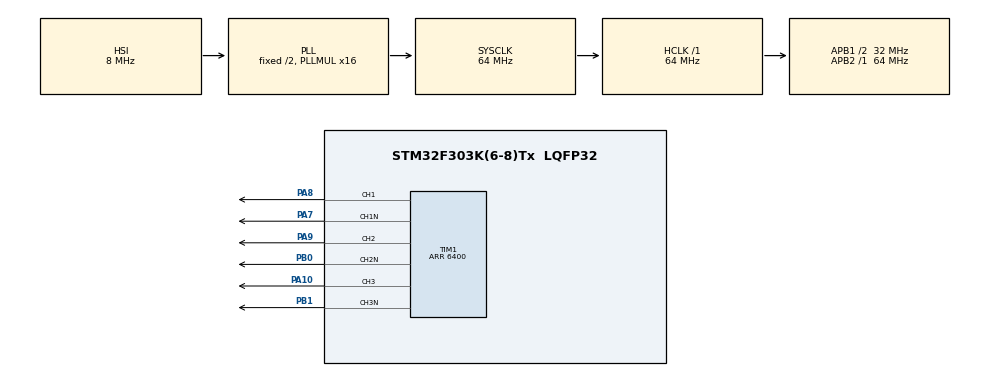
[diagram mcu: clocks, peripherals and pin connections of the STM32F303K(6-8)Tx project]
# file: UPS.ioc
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Mcu.Family=STM32F3
Mcu.Name=STM32F303K(6-8)Tx
Mcu.Package=LQFP32
NVIC.PriorityGroup=NVIC_PRIORITYGROUP_4
NVIC.TIM6_DAC1_IRQn=true\:0\:0\:false\:false\:true\:true
PA10.GPIO_ModeDefaultPP=GPIO_MODE_AF_OD
PA10.GPIO_PuPd=GPIO_PULLUP
PA10.GPIO_Speed=GPIO_SPEED_FREQ_HIGH
PA10.Signal=S_TIM1_CH3
PA7.GPIO_ModeDefaultPP=GPIO_MODE_AF_OD
PA7.GPIO_PuPd=GPIO_PULLUP
PA7.GPIO_Speed=GPIO_SPEED_FREQ_HIGH
PA7.Mode=PWM Generation1 CH1 CH1N
PA7.Signal=TIM1_CH1N
PA8.GPIO_ModeDefaultPP=GPIO_MODE_AF_OD
PA8.GPIO_PuPd=GPIO_PULLUP
PA8.GPIO_Speed=GPIO_SPEED_FREQ_HIGH
PA8.Signal=S_TIM1_CH1
PA9.GPIO_ModeDefaultPP=GPIO_MODE_AF_OD
PA9.GPIO_PuPd=GPIO_PULLUP
PA9.GPIO_Speed=GPIO_SPEED_FREQ_HIGH
PA9.Signal=S_TIM1_CH2
PB0.GPIO_ModeDefaultPP=GPIO_MODE_AF_OD
PB0.GPIO_PuPd=GPIO_PULLUP
PB0.GPIO_Speed=GPIO_SPEED_FREQ_HIGH
PB0.Mode=PWM Generation2 CH2 CH2N
PB0.Signal=TIM1_CH2N
PB1.GPIO_ModeDefaultPP=GPIO_MODE_AF_OD
PB1.GPIO_PuPd=GPIO_PULLUP
PB1.GPIO_Speed=GPIO_SPEED_FREQ_HIGH
PB1.Mode=PWM Generation3 CH3 CH3N
PB1.Signal=TIM1_CH3N
ProjectManager.HeapSize=0x200
ProjectManager.StackSize=0x400
ProjectManager.TargetToolchain=MDK-ARM V5
RCC.AHBFreq_Value=64000000
RCC.APB1CLKDivider=RCC_HCLK_DIV2
RCC.APB1Freq_Value=32000000
RCC.APB1TimFreq_Value=64000000
RCC.APB2Freq_Value=64000000
RCC.APB2TimFreq_Value=64000000
RCC.CortexFreq_Value=64000000
RCC.HCLKFreq_Value=64000000
RCC.HSE_VALUE=8000000
RCC.HSI_VALUE=8000000
RCC.PLLMUL=RCC_PLL_MUL16
RCC.SYSCLKFreq_VALUE=64000000
RCC.SYSCLKSourceVirtual=RCC_SYSCLKSOURCE_PLLCLK
SH.S_TIM1_CH1.0=TIM1_CH1,PWM Generation1 CH1 CH1N
SH.S_TIM1_CH2.0=TIM1_CH2,PWM Generation2 CH2 CH2N
SH.S_TIM1_CH3.0=TIM1_CH3,PWM Generation3 CH3 CH3N
TIM1.Channel-PWM\ Generation1\ CH1\ CH1N=TIM_CHANNEL_1
TIM1.Channel-PWM\ Generation2\ CH2\ CH2N=TIM_CHANNEL_2
TIM1.Channel-PWM\ Generation3\ CH3\ CH3N=TIM_CHANNEL_3
TIM1.DeadTime=50
TIM1.Period=6400
TIM6.Period=6400
VP_TIM1_VS_ClockSourceINT.Mode=Internal
VP_TIM6_VS_ClockSourceINT.Mode=Enable_Timer
board=UPS

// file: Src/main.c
/**
  ******************************************************************************
  * File Name          : main.c
  * Description        : Main program body
  ******************************************************************************
  ** This notice applies to any and all portions of this file
  * that are not between comment pairs USER CODE BEGIN and
  * USER CODE END. Other portions of this file, whether
  * inserted by the user or by software development tools
  * are owned by their respective copyright owners.
  *
  * COPYRIGHT(c) 2023 STMicroelectronics
  *
  * Redistribution and use in source and binary forms, with or without modification,
  * are permitted provided that the following conditions are met:
  *   1. Redistributions of source code must retain the above copyright notice,
  *      this list of conditions and the following disclaimer.
  *   2. Redistributions in binary form must reproduce the above copyright notice,
  *      this list of conditions and the following disclaimer in the documentation
  *      and/or other materials provided with the distribution.
  *   3. Neither the name of STMicroelectronics nor the names of its contributors
  *      may be used to endorse or promote products derived from this software
  *      without specific prior written permission.
  *
  * THIS SOFTWARE IS PROVIDED BY THE COPYRIGHT HOLDERS AND CONTRIBUTORS "AS IS"
  * AND ANY EXPRESS OR IMPLIED WARRANTIES, INCLUDING, BUT NOT LIMITED TO, THE
  * IMPLIED WARRANTIES OF MERCHANTABILITY AND FITNESS FOR A PARTICULAR PURPOSE ARE
  * DISCLAIMED. IN NO EVENT SHALL THE COPYRIGHT HOLDER OR CONTRIBUTORS BE LIABLE
  * FOR ANY DIRECT, INDIRECT, INCIDENTAL, SPECIAL, EXEMPLARY, OR CONSEQUENTIAL
  * DAMAGES (INCLUDING, BUT NOT LIMITED TO, PROCUREMENT OF SUBSTITUTE GOODS OR
  * SERVICES; LOSS OF USE, DATA, OR PROFITS; OR BUSINESS INTERRUPTION) HOWEVER
  * CAUSED AND ON ANY THEORY OF LIABILITY, WHETHER IN CONTRACT, STRICT LIABILITY,
  * OR TORT (INCLUDING NEGLIGENCE OR OTHERWISE) ARISING IN ANY WAY OUT OF THE USE
  * OF THIS SOFTWARE, EVEN IF ADVISED OF THE POSSIBILITY OF SUCH DAMAGE.
  *
  ******************************************************************************
  */

#include "main.h"
#include "stm32f3xx_hal.h"
#include "tim.h"
#include "gpio.h"

/* USER CODE BEGIN PV */
/* Private variables ---------------------------------------------------------*/

/* USER CODE END PV */

void SystemClock_Config(void);

/* USER CODE BEGIN PFP */
/* Private function prototypes -----------------------------------------------*/

/* USER CODE END PFP */

int main(void)
{

  /* MCU Configuration----------------------------------------------------------*/

  /* Reset of all peripherals, Initializes the Flash interface and the Systick. */
  HAL_Init();

  /* Configure the system clock */
  SystemClock_Config();

  /* Initialize all configured peripherals */
  MX_GPIO_Init();
  MX_TIM1_Init();
  MX_TIM6_Init();

  /* USER CODE BEGIN 2 */
	HAL_TIM_PWM_Start(&htim1, TIM_CHANNEL_1);
	HAL_TIMEx_PWMN_Start(&htim1, TIM_CHANNEL_1); // turn on complementary channel
	HAL_TIM_PWM_Start(&htim1, TIM_CHANNEL_2);
	HAL_TIMEx_PWMN_Start(&htim1, TIM_CHANNEL_2); // turn on complementary channel
	HAL_TIM_PWM_Start(&htim1, TIM_CHANNEL_3);
	HAL_TIMEx_PWMN_Start(&htim1, TIM_CHANNEL_3); // turn on complementary channel

	TIM6->DIER |= TIM_DIER_UIE; // enable interrupt from tim6
	TIM6->CR1 |= TIM_CR1_CEN;	// enable tim6
  /* USER CODE END 2 */

  /* Infinite loop */
  while (1)
  {

  /* USER CODE BEGIN 3 */
	//HAL_Delay(1);
  }
  /* USER CODE END 3 */

}

/** System Clock Configuration
*/
void SystemClock_Config(void)
{

  RCC_OscInitTypeDef RCC_OscInitStruct;
  RCC_ClkInitTypeDef RCC_ClkInitStruct;
  RCC_PeriphCLKInitTypeDef PeriphClkInit;

    /**Initializes the CPU, AHB and APB busses clocks
    */
  RCC_OscInitStruct.OscillatorType = RCC_OSCILLATORTYPE_HSI;
  RCC_OscInitStruct.HSIState = RCC_HSI_ON;
  RCC_OscInitStruct.HSICalibrationValue = 16;
  RCC_OscInitStruct.PLL.PLLState = RCC_PLL_ON;
  RCC_OscInitStruct.PLL.PLLSource = RCC_PLLSOURCE_HSI;
  RCC_OscInitStruct.PLL.PLLMUL = RCC_PLL_MUL16;
  if (HAL_RCC_OscConfig(&RCC_OscInitStruct) != HAL_OK)
  {
    _Error_Handler(__FILE__, __LINE__);
  }

    /**Initializes the CPU, AHB and APB busses clocks
    */
  RCC_ClkInitStruct.ClockType = RCC_CLOCKTYPE_HCLK|RCC_CLOCKTYPE_SYSCLK
                              |RCC_CLOCKTYPE_PCLK1|RCC_CLOCKTYPE_PCLK2;
  RCC_ClkInitStruct.SYSCLKSource = RCC_SYSCLKSOURCE_PLLCLK;
  RCC_ClkInitStruct.AHBCLKDivider = RCC_SYSCLK_DIV1;
  RCC_ClkInitStruct.APB1CLKDivider = RCC_HCLK_DIV2;
  RCC_ClkInitStruct.APB2CLKDivider = RCC_HCLK_DIV1;

  if (HAL_RCC_ClockConfig(&RCC_ClkInitStruct, FLASH_LATENCY_2) != HAL_OK)
  {
    _Error_Handler(__FILE__, __LINE__);
  }

  PeriphClkInit.PeriphClockSelection = RCC_PERIPHCLK_TIM1;
  PeriphClkInit.Tim1ClockSelection = RCC_TIM1CLK_HCLK;
  if (HAL_RCCEx_PeriphCLKConfig(&PeriphClkInit) != HAL_OK)
  {
    _Error_Handler(__FILE__, __LINE__);
  }

    /**Configure the Systick interrupt time
    */
  HAL_SYSTICK_Config(HAL_RCC_GetHCLKFreq()/1000);

    /**Configure the Systick
    */
  HAL_SYSTICK_CLKSourceConfig(SYSTICK_CLKSOURCE_HCLK);

  /* SysTick_IRQn interrupt configuration */
  HAL_NVIC_SetPriority(SysTick_IRQn, 0, 0);
}

void _Error_Handler(char * file, int line)
{
  while(1)
  {
  }
}

/************************ (C) COPYRIGHT STMicroelectronics *****END OF FILE****/
